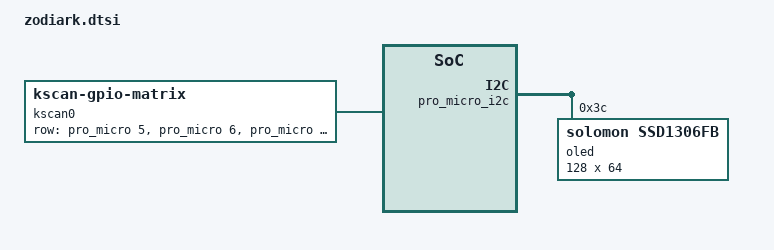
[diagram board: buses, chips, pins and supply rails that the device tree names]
/*
 * Copyright (c) 2021 The ZMK Contributors
 *
 * SPDX-License-Identifier: MIT
 */

#include <dt-bindings/zmk/matrix_transform.h>
#include "zodiark-layouts.dtsi"



/ {
    chosen {
        zephyr,display = &oled;
        zmk,kscan = &kscan0;
        zmk,physical-layout = &physical_layout0;
    };



    kscan0: kscan {
        compatible = "zmk,kscan-gpio-matrix";
        wakeup-source;

        diode-direction = "col2row";
        row-gpios
            = <&pro_micro 5 (GPIO_ACTIVE_HIGH | GPIO_PULL_DOWN)>
            , <&pro_micro 6 (GPIO_ACTIVE_HIGH | GPIO_PULL_DOWN)>
            , <&pro_micro 7 (GPIO_ACTIVE_HIGH | GPIO_PULL_DOWN)>
            , <&pro_micro 8 (GPIO_ACTIVE_HIGH | GPIO_PULL_DOWN)>
            , <&pro_micro 3 (GPIO_ACTIVE_HIGH | GPIO_PULL_DOWN)>
            ;
    };

    left_encoder: encoder_left {
        compatible = "alps,ec11";
        a-gpios = <&pro_micro 2 (GPIO_ACTIVE_HIGH | GPIO_PULL_UP)>;
        b-gpios = <&pro_micro 4 (GPIO_ACTIVE_HIGH | GPIO_PULL_UP)>;
        steps = <80>;
        status = "disabled";
    };

    right_encoder: encoder_right {
        compatible = "alps,ec11";
        a-gpios = <&pro_micro 4 (GPIO_ACTIVE_HIGH | GPIO_PULL_UP)>;
        b-gpios = <&pro_micro 2 (GPIO_ACTIVE_HIGH | GPIO_PULL_UP)>;
        steps = <80>;
        status = "disabled";
    };

    sensors: sensors {
        compatible = "zmk,keymap-sensors";
        sensors = <&left_encoder &right_encoder>;
        triggers-per-rotation = <20>;
    };
};

&pro_micro_i2c {
    status = "okay";

    oled: ssd1306@3c {
        compatible = "solomon,ssd1306fb";
        reg = <0x3c>;
        width = <128>;
        height = <64>;
        segment-offset = <0>;
        page-offset = <0>;
        display-offset = <0>;
        multiplex-ratio = <31>;
        prechargep = <0x22>;
        inversion-on;
    };
};
